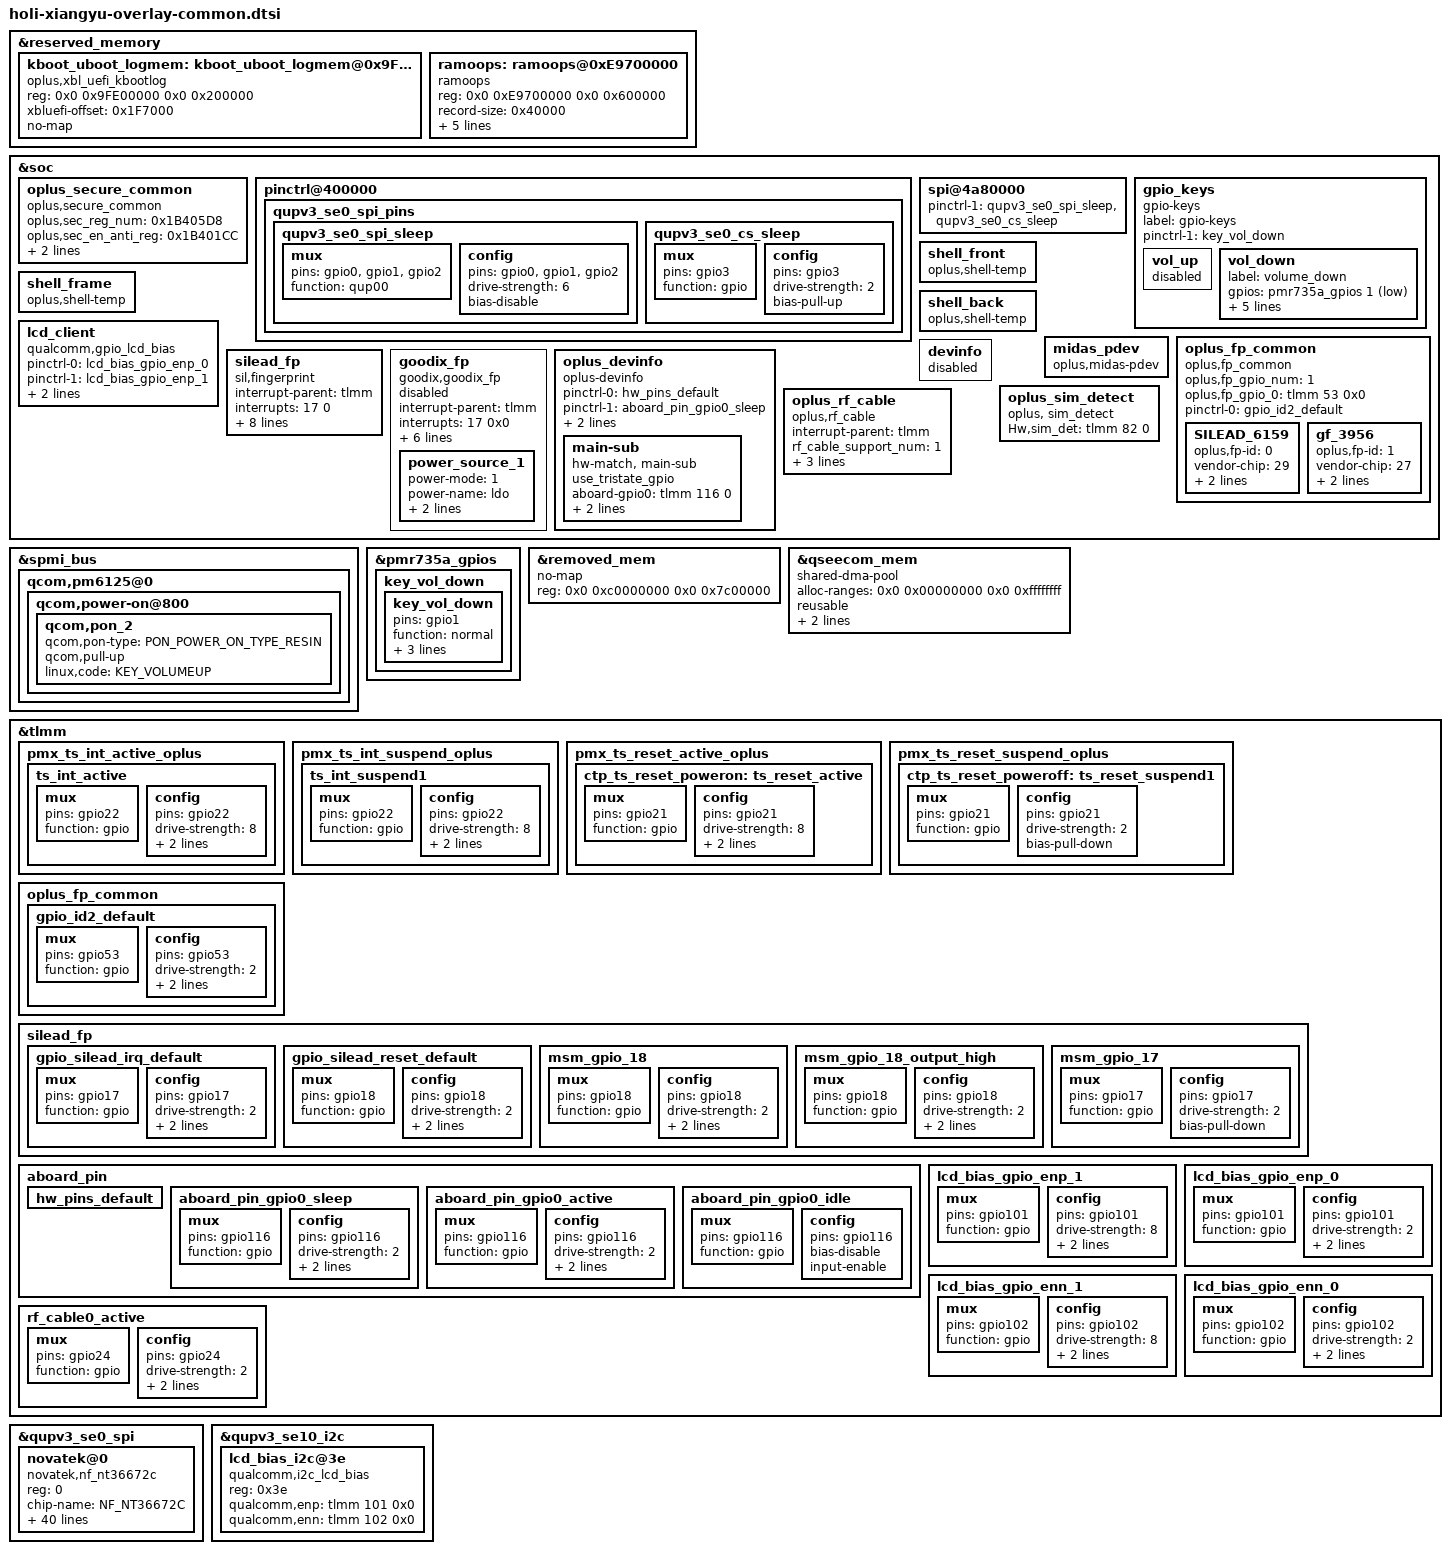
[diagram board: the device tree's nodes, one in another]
#include "../qcom/blair-qrd-nopmi.dtsi"

/* #ifdef OPLUS_ARCH_EXTENDS */
#include "holi-xiangyu-audio-overlay.dtsi"
/* #endif OPLUS_ARCH_EXTENDS */
/* DTBO: Platform common generic overlay */

&reserved_memory {
	//xbl_uefi_mem address get from: PcdEmbeddedFdBaseAddress +
	//SERIAL_BUFFER_OFFSET = 0x9FC00000 + 0x3F7000 = 0x9FFF7000
	//kernel boot log: 0x9FE00000~ 0x9FFF6FFF, xbl-uefi log: 0x9FFF7000 ~ 0x9FFFFFFF
	kboot_uboot_logmem: kboot_uboot_logmem@0x9FE00000 {
		reg = <0x0 0x9FE00000 0x0 0x200000>;
		compatible = "oplus,xbl_uefi_kbootlog";
		xbluefi-offset = <0x1F7000>;
		no-map;
	};

	//#if IS_ENABLED(CONFIG_OPLUS_FEATURE_DUMP_DEVICE_INFO)
	ramoops: ramoops@0xE9700000 {
		compatible = "ramoops";
		reg = <0x0 0xE9700000 0x0 0x600000>;  //6M
		record-size  = <0x40000>; //256k
		console-size = <0x40000>; //256k
		ftrace-size  = <0x100000>; //1M
		pmsg-size    = <0x100000>; //1M
		devinfo-size = <0x8000>;  //32k
		ecc-size     = <0x0>;
	 };
};

&soc{
	oplus_secure_common {
		compatible = "oplus,secure_common";
		oplus,sec_reg_num = <0x1B405D8>;
		oplus,sec_en_anti_reg = <0x1B401CC>;
		oplus,sec_override1_reg = <0x7860C0>;
		oplus,override1_en_value = <0x1>;
	};

	pinctrl@400000 {
		qupv3_se0_spi_pins {
			qupv3_se0_spi_sleep: qupv3_se0_spi_sleep {
				/delete-node/ mux;
				/delete-node/ config;
				mux {
					pins = "gpio0", "gpio1",
							"gpio2";
					function = "qup00";
				};

				config {
					pins = "gpio0", "gpio1",
							"gpio2";
					drive-strength = <6>;
					bias-disable;
				};
			};

			qupv3_se0_cs_sleep: qupv3_se0_cs_sleep {
				mux {
					pins = "gpio3";
					function = "gpio";
				};

				config {
					pins = "gpio3";
					drive-strength = <2>;
					/*bias-disable;*/
					bias-pull-up;
				};
			};
		};
	};

	spi@4a80000 {
		pinctrl-1 = <&qupv3_se0_spi_sleep &qupv3_se0_cs_sleep>;
	};
};

&soc {
/*#ifdef OPLUS_FEATURE_TP_BASIC*/
	gpio_keys {
		compatible = "gpio-keys";
		label = "gpio-keys";

		pinctrl-names = "default";
		pinctrl-1 = <&key_vol_down>;
		/* using volume down config update the default value */

		vol_up {
                status="disabled";
		};

		vol_down {
			label = "volume_down";
			gpios = <&pmr735a_gpios 1 GPIO_ACTIVE_LOW>;
			linux,input-type = <1>;
			linux,code = <KEY_VOLUMEDOWN>;
			gpio-key,wakeup;
			debounce-interval = <15>;
			linux,can-disable;
		};
	};

	shell_front {
		compatible = "oplus,shell-temp";
	};

	shell_frame {
		compatible = "oplus,shell-temp";
	};

	shell_back {
		compatible = "oplus,shell-temp";
	};

	//#ifdef OPLUS_BUG_STABILITY
	lcd_client {
		compatible = "qualcomm,gpio_lcd_bias";
		pinctrl-names = "lcd_bias_gpio_enp0","lcd_bias_gpio_enp1","lcd_bias_gpio_enn0","lcd_bias_gpio_enn1";
		pinctrl-0 = <&lcd_bias_gpio_enp_0>;
		pinctrl-1 = <&lcd_bias_gpio_enp_1>;
		pinctrl-2 = <&lcd_bias_gpio_enn_0>;
		pinctrl-3 = <&lcd_bias_gpio_enn_1>;
		status = "okay";
	};
	//#endif

	midas_pdev {
                compatible = "oplus,midas-pdev";
        };
};

&spmi_bus {
	qcom,pm6125@0 {
		qcom,power-on@800 {
/*#ifdef OPLUS_FEATURE_TP_BASIC*/
			qcom,pon_2 {
					qcom,pon-type = <PON_POWER_ON_TYPE_RESIN>;
					qcom,pull-up;
					linux,code = <KEY_VOLUMEUP>;
			};
/*#endif OPLUS_FEATURE_TP_BASIC*/
		};
	};
};

&pmr735a_gpios {
	key_vol_down {
		key_vol_down: key_vol_down {
			pins = "gpio1";
			function = "normal";
			input-enable;
			bias-pull-up;
			power-source = <1>;
		};
	};
};

/* #ifdef OPLUS_FEATURE_CAMERA_COMMON */
//#include "camera/blair-camera-sensor-mtp.dtsi"
/* #endif OPLUS_FEATURE_CAMERA_COMMON */

//#ifdef OPLUS_FEATURE_FINGERPRINT
&soc{
	oplus_fp_common {
		compatible = "oplus,fp_common";
		oplus,fp_gpio_num = <1>;
		oplus,fp_gpio_0 = <&tlmm 53 0x0>;
		pinctrl-names = "default";
		pinctrl-0 = <&gpio_id2_default>;
		SILEAD_6159 {
			oplus,fp-id = <0>; /* fp id mapping table */
			vendor-chip = <29>; /* please refer to the struct fp_vendor_t in oplus_fp_commmon.h */
			eng-menu = "-1,-1"; /* represents SNR, inclination test item in engineer menu, and 0/1 means off/on */
			chip-name = "S_gsl6159";  /* /proc/fp_id, will be displayed in engineer menu  */
		};
	    gf_3956 {
            oplus,fp-id = <1>; /* fp id mapping table */
            vendor-chip = <27>; /* please refer to the struct fp_vendor_t in oplus_fp_commmon.n */
            eng-menu = "-1,-1"; /* represents SNR, inclination test item in engineer menu, and 0/1 means off/on */
            chip-name = "G_3956";  /* /proc/fp_id, will be displayed in engineer menu  */
    	};

	};

	silead_fp {
		status = "okay";
		compatible = "sil,fingerprint";
		interrupt-parent = <&tlmm>;
		interrupts = <17 0>;
		avdd-supply = <&pm6125_l21>;
		irq-gpios = <&tlmm 17 0x1>;
		rst-gpios = <&tlmm 18 0x0>;
		pinctrl-names = "default", "silead_reset_reset", "silead_reset_active", "silead_irq_active";
		pinctrl-0 = <&gpio_silead_irq_default>, <&gpio_silead_reset_default>;
		pinctrl-1 = <&msm_gpio_18>;
		pinctrl-2 = <&msm_gpio_18_output_high>;
		pinctrl-3 = <&msm_gpio_17>;
	};

	goodix_fp {
		status = "disabled";
		compatible = "goodix,goodix_fp";
		interrupt-parent = <&tlmm>;
		interrupts = <17 0x0>;
		//ldo-supply = <&L21A>;
		//power-mode = <1>;
		ldo-supply = <&pm6125_l21>;
		goodix,gpio_irq = <&tlmm 17 0x00>;
		goodix,gpio_reset = <&tlmm 18 0x00>;
		//gpio-power = <&tlmm 47 0x0>;
		notify_tpinfo_flag = <1>;
		ftm_poweroff_flag = <1>;
		ldo-config = <3300000 3300000 150000>;
		power_source_1 {
			power-mode = <1>;
			power-name = "ldo";
			power-config = "ldo-config";
			delay-time = <0>;
		};
		
	};
};
&removed_mem {
	no-map;
	//reg = <0x0 0xc0000000 0x0 0x5100000>;
	reg = <0x0 0xc0000000 0x0 0x7c00000>;
};

&qseecom_mem {
	compatible = "shared-dma-pool";
	alloc-ranges = <0x0 0x00000000 0x0 0xffffffff>;
	reusable;
	alignment = <0x0 0x400000>;
	//size = <0x0 0x1400000>;
	size = <0x0 0x5c00000>;
};
//#endif /*OPLUS_FEATURE_FINGERPRINT*

//#ifdef OPLUS_FEATURE_TP_BASIC
&soc {
	devinfo {
		status = "disabled";
	};
	oplus_devinfo {
		compatible = "oplus-devinfo";

		pinctrl-names = "default", "sleep", "active", "idle";
		pinctrl-0 = <&hw_pins_default>;
		pinctrl-1 = <&aboard_pin_gpio0_sleep>;
		pinctrl-2 = <&aboard_pin_gpio0_active>;
		pinctrl-3 = <&aboard_pin_gpio0_idle>;
		main-sub {
			use_tristate_gpio;
			compatible = "hw-match, main-sub";
			aboard-gpio0 = <&tlmm 116 0>;
			aboard-patterns = <0>;	/*0[high-resistance] 1[pull-down] 2[pull-up]*/
			/*main board*/
			match-projects = <21039>;
		};
	};

    //#ifdef OPLUS_FEATURE_TP_BASIC
	oplus_sim_detect {
		compatible = "oplus, sim_detect";
		Hw,sim_det = <&tlmm 82 0>;
	};
    //#endif /* OPLUS_FEATURE_TP_BASIC */
};

&tlmm {
	/* add pingrp for touchscreen */
	pmx_ts_int_active_oplus {
		ts_int_active: ts_int_active {
			mux {
				pins = "gpio22";
				function = "gpio";
			};

			config {
				pins = "gpio22";
				drive-strength = <8>;
				bias-disable;
				input-enable;
			};
		};
	};

	pmx_ts_int_suspend_oplus {
		ts_int_suspend1: ts_int_suspend1 {
			mux {
				pins = "gpio22";
				function = "gpio";
			};

			config {
				pins = "gpio22";
				drive-strength = <8>;
				//bias-pull-down;
				bias-pull-up;
				input-enable;
			};
		};
	};

	pmx_ts_reset_active_oplus {
		ctp_ts_reset_poweron: ts_reset_active {
			mux {
				pins = "gpio21";
				function = "gpio";
			};

			config {
				pins = "gpio21";
				drive-strength = <8>;
				output-low;
				bias-disable;
			};
		};
	};

	pmx_ts_reset_suspend_oplus {
		ctp_ts_reset_poweroff: ts_reset_suspend1 {
			mux {
				pins = "gpio21";
				function = "gpio";
			};

			config {
				pins = "gpio21";
				drive-strength = <2>;
				bias-pull-down;
			};
		};
	};

	//#ifdef OPLUS_FEATURE_FINGERPRINT
	oplus_fp_common{
		gpio_id2_default: gpio_id2_default {
			mux {
				pins = "gpio53";
				function = "gpio";
			};
			config {
				pins = "gpio53";
				drive-strength = <2>;
				bias-pull-up;
				input-enable;
			};
		};
	};

	silead_fp{
		gpio_silead_irq_default: gpio_silead_irq_default {
			mux {
				pins = "gpio17";
				function = "gpio";
			};
			config {
				pins = "gpio17";
				drive-strength = <2>;
				bias-pull-down;
				input-enable;
			};
		};
		gpio_silead_reset_default: gpio_silead_reset_default {
			mux {
				pins = "gpio18";
				function = "gpio";
			};
			config {
				pins = "gpio18";
				drive-strength = <2>;
				bias-disable;
				output-low;
			};
		};

		msm_gpio_18: msm_gpio_18 {
			mux {
				pins = "gpio18";
				function = "gpio";
			};

			config {
				pins = "gpio18";
				drive-strength = <2>;
				bias-disable;
				output-low;
			};
		};

		msm_gpio_18_output_high: msm_gpio_18_output_high {
			mux {
				pins = "gpio18";
				function = "gpio";
			};

			config {
				pins = "gpio18";
				drive-strength = <2>;
				bias-disable;
				output-high;
			};
		};

		msm_gpio_17: msm_gpio_17 {
			mux {
				pins = "gpio17";
				function = "gpio";
			};

			config {
				pins = "gpio17";
				drive-strength = <2>;
				bias-pull-down;
			};
		};
	};
	//#endif /*OPLUS_FEATURE_FINGERPRINT*

	//#ifdef OPLUS_FEATURE_TP_BASIC
        aboard_pin {
		hw_pins_default:hw_pins_default {
		};

		aboard_pin_gpio0_sleep:aboard_pin_gpio0_sleep {
			mux {
				pins = "gpio116";
				function = "gpio";
			};
			config {
				pins = "gpio116";
				drive-strength = <2>;
				bias-pull-down;
				input-enable;
			};
		};

		aboard_pin_gpio0_active:aboard_pin_gpio0_active {
			mux {
				pins = "gpio116";
				function = "gpio";
			};
			config {
				pins = "gpio116";
				drive-strength = <2>;
				bias-pull-up;
				input-enable;
			};
		};

		aboard_pin_gpio0_idle:aboard_pin_gpio0_idle {
			mux {
				pins = "gpio116";
				function = "gpio";
			};
			config {
				pins = "gpio116";
				bias-disable;
				input-enable;
			};
		};
	};
	//#endif /*OPLUS_FEATURE_TP_BASIC*/

	//#ifdef OPLUS_BUG_STABILITY
	lcd_bias_gpio_enp_1: lcd_bias_gpio_enp_1 {
		mux {
			pins = "gpio101";
			function = "gpio";
		};

		config {
			pins = "gpio101";
			drive-strength = <8>;
			output-high;
			bias-pull-up;
		};
	};

	lcd_bias_gpio_enp_0: lcd_bias_gpio_enp_0 {
		mux {
			pins = "gpio101";
			function = "gpio";
		};

		config {
			pins = "gpio101";
			drive-strength = <2>;
			output-low;
			bias-pull-down;
		};
	};

	lcd_bias_gpio_enn_1: lcd_bias_gpio_enn_1 {
		mux {
			pins = "gpio102";
			function = "gpio";
		};

		config {
			pins = "gpio102";
			drive-strength = <8>;
			output-high;
			bias-pull-up;
		};
	};

	lcd_bias_gpio_enn_0: lcd_bias_gpio_enn_0 {
		mux {
			pins = "gpio102";
			function = "gpio";
		};

		config {
			pins = "gpio102";
			drive-strength = <2>;
			output-low;
			bias-pull-down;
		};
	};
	//#endif
};

#include "xiangyu-21039-tp.dtsi"
&qupv3_se0_spi {
	status = "ok";
	novatek@0 {
		compatible = "novatek,nf_nt36672c";
		reg = <0>;
		chip-name = "NF_NT36672C";
		status = "ok";

		spi-max-frequency = <12000000>;    /*4800000,9600000,15000000,19200000*/
		reset-gpio = <&tlmm 21 0x00>;
		interrupt-parent = <&tlmm>;
		interrupts = <22  0x0>;
		irq-gpio = <&tlmm 22 0x2002>;
		cs-gpio = <&tlmm 3 0x00>;

		touchpanel,irq_need_dev_resume_time = <500>;
		touchpanel,max-num-support = <10>;
		touchpanel,tx-rx-num = <18 36>;
		touchpanel,panel-coords = <1080 2280>;
		touchpanel,display-coords = <1080 2280>;
		touchpanel,touchmajor-limit = <0 54>;

		platform_support_project = <21039>;
		platform_support_project_dir = <21039>;
		platform_support_project_commandline = "nt36672c_tm";
		pinctrl-names = "default", "pin_set_low", "pin_set_high";
		pinctrl-0 = <&ts_int_active>;
		pinctrl-1 = <&ctp_ts_reset_poweroff>;
		pinctrl-2 = <&ctp_ts_reset_poweron>;

		panel_type = <7>;	/*TM*/
		tp_type = <7>;
		project_id = <21039>;
		firmware_name = "0xAA35600";

		incell_screen;
		fw_edge_limit_support;
		black_gesture_support;
		charger_pump_support;
		headset_pump_support;
		esd_handle_support;
		black_gesture_test_support;
		noflash_support;
		smart_gesture_support;
		pressure_report_support;
		fw_update_app_support;
		game_switch_support;
		new_set_irq_wake_support;
		lcd_trigger_load_tp_fw_support;
		fw_update_in_probe_with_headfile;
		health_monitor_support;
		touchpanel,button-type = <4>;
	};
};

&qupv3_se10_i2c {
	#address-cells = <1>;
	#size-cells = <0>;

	status = "ok";

	//#ifdef OPLUS_BUG_STABILITY
	lcd_bias_i2c@3e {
		compatible = "qualcomm,i2c_lcd_bias";
		reg = <0x3e>;
		qualcomm,enp = <&tlmm 101 0x0>;
		qualcomm,enn = <&tlmm 102 0x0>;
		status = "okay";
	};
	//#endif
};

//#ifdef OPLUS_FEATURE_RF_CALBLE
&tlmm {
	rf_cable0_active: rf_cable0_active {
		mux {
			pins = "gpio24";
			function = "gpio";
		};
		config {
			pins = "gpio24";
			drive-strength = <2>;
			input-enable;
			bias-pull-down;
		};
	};
};

&soc {
	oplus_rf_cable {
		compatible = "oplus,rf_cable";
		interrupt-parent = <&tlmm>;
		rf_cable_support_num = <1>;
		rf,cable0-gpio = <&tlmm 24 0>;
		rf,cable-support-timer = <0>;
		pinctrl-names = "rf_cable_active";
		pinctrl-0 = <&rf_cable0_active>;
	};
};
//#endif /*OPLUS_FEATURE_RF_CALBLE*/

//#ifdef OPLUS_FEATURE_NFC_BRINGUP
#include "nfc/xiangyu-21708-nfc-pn557.dtsi"
//#endif /* OPLUS_FEATURE_NFC_BRINGUP */
